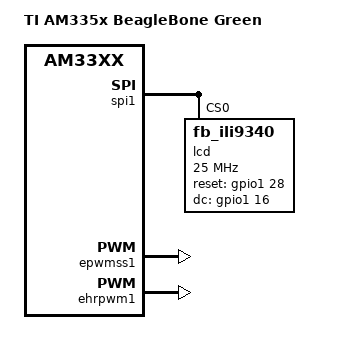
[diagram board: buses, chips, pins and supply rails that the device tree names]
/*
 * Copyright (C) 2012 Texas Instruments Incorporated - http://www.ti.com/
 *
 * This program is free software; you can redistribute it and/or modify
 * it under the terms of the GNU General Public License version 2 as
 * published by the Free Software Foundation.
 * Modified by Abhilash to enable the ili9341 LCD at boot.
 * 
 */
/dts-v1/;
/plugin/;

#include "am33xx.dtsi"
#include "am335x-bone-common.dtsi"
#include "am335x-bonegreen-common.dtsi"

/ {
	model = "TI AM335x BeagleBone Green";
	compatible = "ti,am335x-bone-green", "ti,am335x-bone-black", "ti,am335x-bone", "ti,am33xx";
	

};

	&am33xx_pinmux{

			
				bb_spi1_pins: pinmux_bb_spi1_pins {
				pinctrl-single,pins = <
					0x190 0x33	/* mcasp0_aclkx.spi1_sclk, INPUT_PULLUP | MODE3 */
					0x194 0x33	/* mcasp0_fsx.spi1_d0, INPUT_PULLUP | MODE3 */
					0x198 0x13	/* mcasp0_axr0.spi1_d1, OUTPUT_PULLUP | MODE3 */
					0x19c 0x13	/* mcasp0_ahclkr.spi1_cs0, OUTPUT_PULLUP | MODE3 */
					// 0x164 0x12	/* eCAP0_in_PWM0_out.spi1_cs1 OUTPUT_PULLUP | MODE2 */
				>;
			};

				lcd_ctrl_pinmux: lcd_ctrl_pins {
				pinctrl-single,pins = <
					0x078 0x17	/* P9_15: gpio1_16 reset, OUTPUT_PULLUP | MODE7 */
					0x040 0x17	/* P9_12: gpio1_28 DC, OUTPUT_PULLUP | MODE7 */
				>;
			};

			

		};
	

	&spi1 {
			status = "okay";
			
			pinctrl-names = "default";
			pinctrl-0 = <&bb_spi1_pins>;

			#address-cells = <1>;
			#size-cells = <0>;

			lcd@0{
				compatible = "fb_ili9340";
				reg = <0>;

				pinctrl-names = "default";
				pinctrl-0 = <&lcd_ctrl_pinmux>;

				spi-max-frequency = <25000000>;
				rotate = <270>;
				bgr;
				fps = <50>;
				buswidth = <8>;
				reset-gpios = <&gpio1 28 0>;
				dc-gpios = <&gpio1 16 0>;

				debug = <1>;
			};
		};





	
&epwmss1 {
	status = "okay";
};

&ehrpwm1 {
	status = "okay";
};

	
